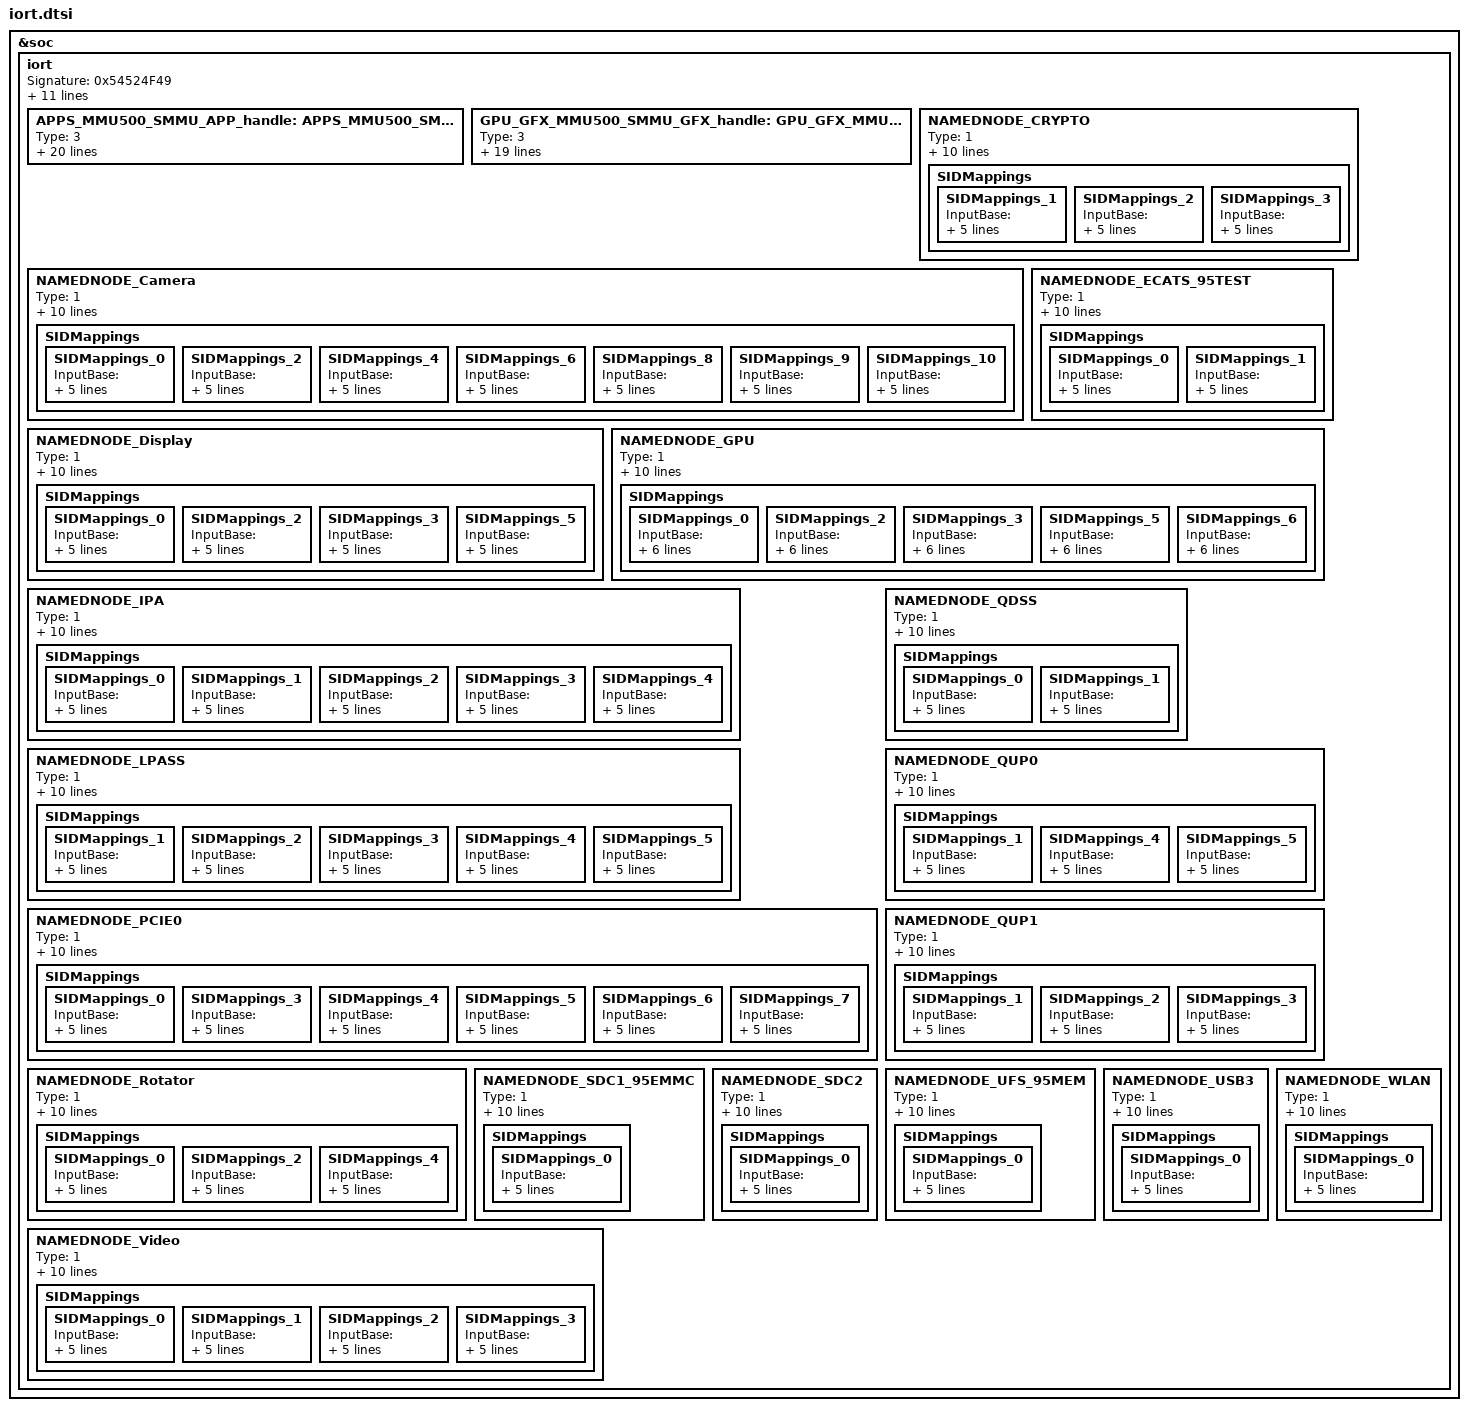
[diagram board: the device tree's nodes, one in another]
/** SMMU IORT Device Tree for clarence_1.0.

This file is automatically generated.
SMMU Base Address and Span information based on Chip Version: clarence_v1.0_p3q3r41_MTO.
Interrupt information based on Interrupt Map Version: Clarence_v1.0_p3q3r41_MTO_tmess_update.
SMMU SID Mappings based on http://ipcatalog.qualcomm.com/hsr/1914 - clarence.sid.mapping.xlsx Version 28.0.

Copyright (c) 2022 Qualcomm Technologies, Inc.
All Rights Reserved.
Confidential and Proprietary - Qualcomm Technologies, Inc.
*/

#include <iort_defines.h>
&soc{
  iort {
    Signature = <0x54524F49>;
    Revision = <1>;
    Checksum = <0>;
    OEMID = ACPI_OEM_ID;
    OEMTableID = <ACPI_OEM_TABLE_ID>;
    OEMRevision = <ACPI_OEM_REVISION>;
    CreatorID = <ACPI_CREATOR_ID>;
    CreatorRevision = <ACPI_CREATOR_REVISION>;
    NumberofIORTNodes = <20>;
    Reserved = <0>;
    instance_handles = < &APPS_MMU500_SMMU_APP_handle  &GPU_GFX_MMU500_SMMU_GFX_handle >;
    
    APPS_MMU500_SMMU_APP_handle:APPS_MMU500_SMMU_APP {
      Type = <3>;
      Revision = <1>;
      Reserved = <0>;
      NumberofMappings = <0>;
      BaseAddress = <0x15000000>; 
      Span = <0x00080000>; 
      Flags = <3>;
      Model = <3>;
      NumContextInterrupts = <96>;
      NumPMUInterrupts = <7>;
      NSGIRPT_GSIV = <97>;
      NSGIRPT_FLAGS = <0>;
      NSGCFGIRPT_GSIV = <0>;
      NSGCFGIRPT_FLAGS = <0>;
      ContextInterrupts = <126 127 128 702 703 129 130 131 132 133 134 135 136 137 138 139 140 141 142 143 144 145 146 147 148 149 150 213 214 215 216 217 218 219 220 221 222 223 224 347 348 349 350 351 352 353 354 355 356 357 358 359 360 361 362 363 364 365 366 367 368 369 370 371 372 373 374 375 376 377 427 428 429 430 431 432 433 434 435 436 437 438 439 440 441 450 451 444 453 738 455 456 457 721 722 723 >;
      ContextInterruptFlags = <0 0 0 0 0 0 0 0 0 0 0 0 0 0 0 0 0 0 0 0 0 0 0 0 0 0 0 0 0 0 0 0 0 0 0 0 0 0 0 0 0 0 0 0 0 0 0 0 0 0 0 0 0 0 0 0 0 0 0 0 0 0 0 0 0 0 0 0 0 0 0 0 0 0 0 0 0 0 0 0 0 0 0 0 0 0 0 0 0 0 0 0 0 0 0 0 >;
      PMUInterrupts = <100 101 102 103 104 105 458 >;
      PMUInterruptFlags = <0 0 0 0 0 0 0 >;
      SIDMAPPING =<0>;
      };
    GPU_GFX_MMU500_SMMU_GFX_handle:GPU_GFX_MMU500_SMMU_GFX {
      Type = <3>;
      Revision = <1>;
      Reserved = <0>;
      NumberofMappings = <0>;
      BaseAddress = <0x03da0000>; 
      Span = <0x00008000>; 
      Flags = <3>;
      Model = <3>;
      NumContextInterrupts = <8>;
      NumPMUInterrupts = <2>;
      NSGIRPT_GSIV = <705>;
      NSGIRPT_FLAGS = <0>;
      NSGCFGIRPT_GSIV = <0>;
      NSGCFGIRPT_FLAGS = <0>;
      ContextInterrupts = <710 711 712 713 714 715 716 717 >;
      ContextInterruptFlags = <0 0 0 0 0 0 0 0 >;
      PMUInterrupts = <708 709 >;
      PMUInterruptFlags = <0 0 >;
      SIDMAPPING =<0>;
      };
    
    
    NAMEDNODE_CRYPTO {
      Type = <1>;
      Revision = <1>;
      Reserved = <0>;
      NumberofMappings = <3>;
      NodeFlags = <0>;
      CacheCoherency = <0>;
      AllocationHints = <0>;
      Reserved1 = <0>;
      MemAccessFlags = <0>;
      DeviceMemAddressSize = <36>;
      DevObjectName = "CRYPTO";
      SIDMappings {
        SIDMappings_1 {
          InputBase = <(
              (IORT_WORLD_ID_NON_SECURE << IORT_WORLD_ID_SHIFT) |
              (IORT_DYNAMIC_MAPPING_NO << IORT_DYNAMIC_MAPPING_SHIFT) |
              (IORT_TRANSLATION_TYPE_NESTED << IORT_TRANSLATION_TYPE_SHIFT) |
              (1))>;
          NumIDs = <1>;
          OutputBase = <0x00000481>;
          Flags = <0>;
          OutputReference = <&APPS_MMU500_SMMU_APP_handle>;
        };
        SIDMappings_2 {
          InputBase = <(
              (IORT_WORLD_ID_NON_SECURE << IORT_WORLD_ID_SHIFT) |
              (IORT_DYNAMIC_MAPPING_NO << IORT_DYNAMIC_MAPPING_SHIFT) |
              (IORT_TRANSLATION_TYPE_NESTED << IORT_TRANSLATION_TYPE_SHIFT) |
              (2))>;
          NumIDs = <1>;
          OutputBase = <0x00000480>;
          Flags = <0>;
          OutputReference = <&APPS_MMU500_SMMU_APP_handle>;
        };
        SIDMappings_3 {
          InputBase = <(
              (IORT_WORLD_ID_NON_SECURE << IORT_WORLD_ID_SHIFT) |
              (IORT_DYNAMIC_MAPPING_NO << IORT_DYNAMIC_MAPPING_SHIFT) |
              (IORT_TRANSLATION_TYPE_NESTED << IORT_TRANSLATION_TYPE_SHIFT) |
              (3))>;
          NumIDs = <1>;
          OutputBase = <0x00000483>;
          Flags = <0>;
          OutputReference = <&APPS_MMU500_SMMU_APP_handle>;
        };
      };
    };
    NAMEDNODE_Camera {
      Type = <1>;
      Revision = <1>;
      Reserved = <0>;
      NumberofMappings = <7>;
      NodeFlags = <0>;
      CacheCoherency = <0>;
      AllocationHints = <0>;
      Reserved1 = <0>;
      MemAccessFlags = <0>;
      DeviceMemAddressSize = <36>;
      DevObjectName = "CAMERA";
      SIDMappings {
        SIDMappings_0 {
          InputBase = <(
              (IORT_WORLD_ID_NON_SECURE << IORT_WORLD_ID_SHIFT) |
              (IORT_DYNAMIC_MAPPING_NO << IORT_DYNAMIC_MAPPING_SHIFT) |
              (IORT_TRANSLATION_TYPE_NESTED << IORT_TRANSLATION_TYPE_SHIFT) |
              (0))>;
          NumIDs = <1>;
          OutputBase = <0x04200880>;
          Flags = <0>;
          OutputReference = <&APPS_MMU500_SMMU_APP_handle>;
        };
        SIDMappings_2 {
          InputBase = <(
              (IORT_WORLD_ID_NON_SECURE << IORT_WORLD_ID_SHIFT) |
              (IORT_DYNAMIC_MAPPING_NO << IORT_DYNAMIC_MAPPING_SHIFT) |
              (IORT_TRANSLATION_TYPE_NESTED << IORT_TRANSLATION_TYPE_SHIFT) |
              (2))>;
          NumIDs = <1>;
          OutputBase = <0x00001800>;
          Flags = <0>;
          OutputReference = <&APPS_MMU500_SMMU_APP_handle>;
        };
        SIDMappings_4 {
          InputBase = <(
              (IORT_WORLD_ID_NON_SECURE << IORT_WORLD_ID_SHIFT) |
              (IORT_DYNAMIC_MAPPING_NO << IORT_DYNAMIC_MAPPING_SHIFT) |
              (IORT_TRANSLATION_TYPE_NESTED << IORT_TRANSLATION_TYPE_SHIFT) |
              (4))>;
          NumIDs = <1>;
          OutputBase = <0x00001820>;
          Flags = <0>;
          OutputReference = <&APPS_MMU500_SMMU_APP_handle>;
        };
        SIDMappings_6 {
          InputBase = <(
              (IORT_WORLD_ID_NON_SECURE << IORT_WORLD_ID_SHIFT) |
              (IORT_DYNAMIC_MAPPING_NO << IORT_DYNAMIC_MAPPING_SHIFT) |
              (IORT_TRANSLATION_TYPE_NESTED << IORT_TRANSLATION_TYPE_SHIFT) |
              (6))>;
          NumIDs = <1>;
          OutputBase = <0x00a01840>;
          Flags = <0>;
          OutputReference = <&APPS_MMU500_SMMU_APP_handle>;
        };
        SIDMappings_8 {
          InputBase = <(
              (IORT_WORLD_ID_NON_SECURE << IORT_WORLD_ID_SHIFT) |
              (IORT_DYNAMIC_MAPPING_NO << IORT_DYNAMIC_MAPPING_SHIFT) |
              (IORT_TRANSLATION_TYPE_NESTED << IORT_TRANSLATION_TYPE_SHIFT) |
              (8))>;
          NumIDs = <1>;
          OutputBase = <0x00001900>;
          Flags = <0>;
          OutputReference = <&APPS_MMU500_SMMU_APP_handle>;
        };
        SIDMappings_9 {
          InputBase = <(
              (IORT_WORLD_ID_NON_SECURE << IORT_WORLD_ID_SHIFT) |
              (IORT_DYNAMIC_MAPPING_NO << IORT_DYNAMIC_MAPPING_SHIFT) |
              (IORT_TRANSLATION_TYPE_NESTED << IORT_TRANSLATION_TYPE_SHIFT) |
              (9))>;
          NumIDs = <1>;
          OutputBase = <0x00001920>;
          Flags = <0>;
          OutputReference = <&APPS_MMU500_SMMU_APP_handle>;
        };
        SIDMappings_10 {
          InputBase = <(
              (IORT_WORLD_ID_NON_SECURE << IORT_WORLD_ID_SHIFT) |
              (IORT_DYNAMIC_MAPPING_NO << IORT_DYNAMIC_MAPPING_SHIFT) |
              (IORT_TRANSLATION_TYPE_NESTED << IORT_TRANSLATION_TYPE_SHIFT) |
              (10))>;
          NumIDs = <1>;
          OutputBase = <0x00001940>;
          Flags = <0>;
          OutputReference = <&APPS_MMU500_SMMU_APP_handle>;
        };
      };
    };
    NAMEDNODE_Display {
      Type = <1>;
      Revision = <1>;
      Reserved = <0>;
      NumberofMappings = <4>;
      NodeFlags = <0>;
      CacheCoherency = <0>;
      AllocationHints = <0>;
      Reserved1 = <0>;
      MemAccessFlags = <0>;
      DeviceMemAddressSize = <36>;
      DevObjectName = "DISPLAY";
      SIDMappings {
        SIDMappings_0 {
          InputBase = <(
              (IORT_WORLD_ID_NON_SECURE << IORT_WORLD_ID_SHIFT) |
              (IORT_DYNAMIC_MAPPING_NO << IORT_DYNAMIC_MAPPING_SHIFT) |
              (IORT_TRANSLATION_TYPE_NESTED << IORT_TRANSLATION_TYPE_SHIFT) |
              (0))>;
          NumIDs = <1>;
          OutputBase = <0x04020800>;
          Flags = <0>;
          OutputReference = <&APPS_MMU500_SMMU_APP_handle>;
        };
        SIDMappings_2 {
          InputBase = <(
              (IORT_WORLD_ID_NON_SECURE << IORT_WORLD_ID_SHIFT) |
              (IORT_DYNAMIC_MAPPING_YES_DEFAULT << IORT_DYNAMIC_MAPPING_SHIFT) |
              (IORT_TRANSLATION_TYPE_NESTED << IORT_TRANSLATION_TYPE_SHIFT) |
              (2))>;
          NumIDs = <1>;
          OutputBase = <0x00000801>;
          Flags = <0>;
          OutputReference = <&APPS_MMU500_SMMU_APP_handle>;
        };
        SIDMappings_3 {
          InputBase = <(
              (IORT_WORLD_ID_NON_SECURE << IORT_WORLD_ID_SHIFT) |
              (IORT_DYNAMIC_MAPPING_NO << IORT_DYNAMIC_MAPPING_SHIFT) |
              (IORT_TRANSLATION_TYPE_NESTED << IORT_TRANSLATION_TYPE_SHIFT) |
              (3))>;
          NumIDs = <1>;
          OutputBase = <0x04020804>;
          Flags = <0>;
          OutputReference = <&APPS_MMU500_SMMU_APP_handle>;
        };
        SIDMappings_5 {
          InputBase = <(
              (IORT_WORLD_ID_NON_SECURE << IORT_WORLD_ID_SHIFT) |
              (IORT_DYNAMIC_MAPPING_YES_DEFAULT << IORT_DYNAMIC_MAPPING_SHIFT) |
              (IORT_TRANSLATION_TYPE_NESTED << IORT_TRANSLATION_TYPE_SHIFT) |
              (5))>;
          NumIDs = <1>;
          OutputBase = <0x00000c01>;
          Flags = <0>;
          OutputReference = <&APPS_MMU500_SMMU_APP_handle>;
        };
      };
    };
    NAMEDNODE_ECATS_95TEST {
      Type = <1>;
      Revision = <1>;
      Reserved = <0>;
      NumberofMappings = <2>;
      NodeFlags = <0>;
      CacheCoherency = <0>;
      AllocationHints = <0>;
      Reserved1 = <0>;
      MemAccessFlags = <0>;
      DeviceMemAddressSize = <36>;
      DevObjectName = "ECATS_TEST";
      SIDMappings {
        SIDMappings_0 {
          InputBase = <(
              (IORT_WORLD_ID_NON_SECURE << IORT_WORLD_ID_SHIFT) |
              (IORT_DYNAMIC_MAPPING_NO << IORT_DYNAMIC_MAPPING_SHIFT) |
              (IORT_TRANSLATION_TYPE_NESTED << IORT_TRANSLATION_TYPE_SHIFT) |
              (0))>;
          NumIDs = <1>;
          OutputBase = <0x000007e0>;
          Flags = <0>;
          OutputReference = <&APPS_MMU500_SMMU_APP_handle>;
        };
        SIDMappings_1 {
          InputBase = <(
              (IORT_WORLD_ID_NON_SECURE << IORT_WORLD_ID_SHIFT) |
              (IORT_DYNAMIC_MAPPING_NO << IORT_DYNAMIC_MAPPING_SHIFT) |
              (IORT_TRANSLATION_TYPE_NESTED << IORT_TRANSLATION_TYPE_SHIFT) |
              (1))>;
          NumIDs = <1>;
          OutputBase = <0x000007e1>;
          Flags = <0>;
          OutputReference = <&APPS_MMU500_SMMU_APP_handle>;
        };
      };
    };
    NAMEDNODE_GPU {
      Type = <1>;
      Revision = <1>;
      Reserved = <0>;
      NumberofMappings = <5>;
      NodeFlags = <0>;
      CacheCoherency = <0>;
      AllocationHints = <0>;
      Reserved1 = <0>;
      MemAccessFlags = <0>;
      DeviceMemAddressSize = <36>;
      DevObjectName = "GPU";
      SIDMappings {
        SIDMappings_0 {
          InputBase = <(
              (IORT_WORLD_ID_NON_SECURE << IORT_WORLD_ID_SHIFT) |
              (IORT_DYNAMIC_MAPPING_NO << IORT_DYNAMIC_MAPPING_SHIFT) |
              (IORT_TRANSLATION_TYPE_NESTED << IORT_TRANSLATION_TYPE_SHIFT) |
              (0))>;
          NumIDs = <1>;
          OutputBase = <0x04000000>;
          Flags = <0>;
          OutputReference = <&GPU_GFX_MMU500_SMMU_GFX_handle>;
        };
        SIDMappings_2 {
          InputBase = <(
              (IORT_WORLD_ID_NON_SECURE << IORT_WORLD_ID_SHIFT) |
              (IORT_DYNAMIC_MAPPING_NO << IORT_DYNAMIC_MAPPING_SHIFT) |
              (IORT_TRANSLATION_TYPE_NESTED << IORT_TRANSLATION_TYPE_SHIFT) |
              (2))>;
          NumIDs = <1>;
          OutputBase = <0x04000001>;
          Flags = <0>;
          OutputReference = <&GPU_GFX_MMU500_SMMU_GFX_handle>;
        };
        SIDMappings_3 {
          InputBase = <(
              (IORT_WORLD_ID_NON_SECURE << IORT_WORLD_ID_SHIFT) |
              (IORT_DYNAMIC_MAPPING_NO << IORT_DYNAMIC_MAPPING_SHIFT) |
              (IORT_TRANSLATION_TYPE_NESTED << IORT_TRANSLATION_TYPE_SHIFT) |
              (3))>;
          NumIDs = <1>;
          OutputBase = <0x04000002>;
          Flags = <0>;
          OutputReference = <&GPU_GFX_MMU500_SMMU_GFX_handle>;
        };
        SIDMappings_5 {
          InputBase = <(
              (IORT_WORLD_ID_NON_SECURE << IORT_WORLD_ID_SHIFT) |
              (IORT_DYNAMIC_MAPPING_NO << IORT_DYNAMIC_MAPPING_SHIFT) |
              (IORT_TRANSLATION_TYPE_NESTED << IORT_TRANSLATION_TYPE_SHIFT) |
              (5))>;
          NumIDs = <1>;
          OutputBase = <0x04000007>;
          Flags = <0>;
          OutputReference = <&GPU_GFX_MMU500_SMMU_GFX_handle>;
        };
        SIDMappings_6 {
          InputBase = <(
              (IORT_WORLD_ID_NON_SECURE << IORT_WORLD_ID_SHIFT) |
              (IORT_DYNAMIC_MAPPING_NO << IORT_DYNAMIC_MAPPING_SHIFT) |
              (IORT_TRANSLATION_TYPE_NESTED << IORT_TRANSLATION_TYPE_SHIFT) |
              (6))>;
          NumIDs = <1>;
          OutputBase = <0x04000009>;
          Flags = <0>;
          OutputReference = <&GPU_GFX_MMU500_SMMU_GFX_handle>;
        };
      };
    };
    NAMEDNODE_IPA {
      Type = <1>;
      Revision = <1>;
      Reserved = <0>;
      NumberofMappings = <5>;
      NodeFlags = <0>;
      CacheCoherency = <0>;
      AllocationHints = <0>;
      Reserved1 = <0>;
      MemAccessFlags = <0>;
      DeviceMemAddressSize = <36>;
      DevObjectName = "IPA";
      SIDMappings {
        SIDMappings_0 {
          InputBase = <(
              (IORT_WORLD_ID_NON_SECURE << IORT_WORLD_ID_SHIFT) |
              (IORT_DYNAMIC_MAPPING_NO << IORT_DYNAMIC_MAPPING_SHIFT) |
              (IORT_TRANSLATION_TYPE_NESTED << IORT_TRANSLATION_TYPE_SHIFT) |
              (0))>;
          NumIDs = <1>;
          OutputBase = <0x000004a0>;
          Flags = <0>;
          OutputReference = <&APPS_MMU500_SMMU_APP_handle>;
        };
        SIDMappings_1 {
          InputBase = <(
              (IORT_WORLD_ID_NON_SECURE << IORT_WORLD_ID_SHIFT) |
              (IORT_DYNAMIC_MAPPING_NO << IORT_DYNAMIC_MAPPING_SHIFT) |
              (IORT_TRANSLATION_TYPE_NESTED << IORT_TRANSLATION_TYPE_SHIFT) |
              (1))>;
          NumIDs = <1>;
          OutputBase = <0x000004a1>;
          Flags = <0>;
          OutputReference = <&APPS_MMU500_SMMU_APP_handle>;
        };
        SIDMappings_2 {
          InputBase = <(
              (IORT_WORLD_ID_NON_SECURE << IORT_WORLD_ID_SHIFT) |
              (IORT_DYNAMIC_MAPPING_NO << IORT_DYNAMIC_MAPPING_SHIFT) |
              (IORT_TRANSLATION_TYPE_NESTED << IORT_TRANSLATION_TYPE_SHIFT) |
              (2))>;
          NumIDs = <1>;
          OutputBase = <0x000004a2>;
          Flags = <0>;
          OutputReference = <&APPS_MMU500_SMMU_APP_handle>;
        };
        SIDMappings_3 {
          InputBase = <(
              (IORT_WORLD_ID_NON_SECURE << IORT_WORLD_ID_SHIFT) |
              (IORT_DYNAMIC_MAPPING_NO << IORT_DYNAMIC_MAPPING_SHIFT) |
              (IORT_TRANSLATION_TYPE_NESTED << IORT_TRANSLATION_TYPE_SHIFT) |
              (3))>;
          NumIDs = <1>;
          OutputBase = <0x000004a3>;
          Flags = <0>;
          OutputReference = <&APPS_MMU500_SMMU_APP_handle>;
        };
        SIDMappings_4 {
          InputBase = <(
              (IORT_WORLD_ID_NON_SECURE << IORT_WORLD_ID_SHIFT) |
              (IORT_DYNAMIC_MAPPING_NO << IORT_DYNAMIC_MAPPING_SHIFT) |
              (IORT_TRANSLATION_TYPE_NESTED << IORT_TRANSLATION_TYPE_SHIFT) |
              (4))>;
          NumIDs = <1>;
          OutputBase = <0x000004a4>;
          Flags = <0>;
          OutputReference = <&APPS_MMU500_SMMU_APP_handle>;
        };
      };
    };
    NAMEDNODE_LPASS {
      Type = <1>;
      Revision = <1>;
      Reserved = <0>;
      NumberofMappings = <5>;
      NodeFlags = <0>;
      CacheCoherency = <0>;
      AllocationHints = <0>;
      Reserved1 = <0>;
      MemAccessFlags = <0>;
      DeviceMemAddressSize = <36>;
      DevObjectName = "LPASS";
      SIDMappings {
        SIDMappings_1 {
          InputBase = <(
              (IORT_WORLD_ID_NON_SECURE << IORT_WORLD_ID_SHIFT) |
              (IORT_DYNAMIC_MAPPING_NO << IORT_DYNAMIC_MAPPING_SHIFT) |
              (IORT_TRANSLATION_TYPE_NESTED << IORT_TRANSLATION_TYPE_SHIFT) |
              (1))>;
          NumIDs = <1>;
          OutputBase = <0x00001001>;
          Flags = <0>;
          OutputReference = <&APPS_MMU500_SMMU_APP_handle>;
        };
        SIDMappings_2 {
          InputBase = <(
              (IORT_WORLD_ID_NON_SECURE << IORT_WORLD_ID_SHIFT) |
              (IORT_DYNAMIC_MAPPING_NO << IORT_DYNAMIC_MAPPING_SHIFT) |
              (IORT_TRANSLATION_TYPE_NESTED << IORT_TRANSLATION_TYPE_SHIFT) |
              (2))>;
          NumIDs = <1>;
          OutputBase = <0x00001003>;
          Flags = <0>;
          OutputReference = <&APPS_MMU500_SMMU_APP_handle>;
        };
        SIDMappings_3 {
          InputBase = <(
              (IORT_WORLD_ID_NON_SECURE << IORT_WORLD_ID_SHIFT) |
              (IORT_DYNAMIC_MAPPING_NO << IORT_DYNAMIC_MAPPING_SHIFT) |
              (IORT_TRANSLATION_TYPE_NESTED << IORT_TRANSLATION_TYPE_SHIFT) |
              (3))>;
          NumIDs = <1>;
          OutputBase = <0x00001004>;
          Flags = <0>;
          OutputReference = <&APPS_MMU500_SMMU_APP_handle>;
        };
        SIDMappings_4 {
          InputBase = <(
              (IORT_WORLD_ID_NON_SECURE << IORT_WORLD_ID_SHIFT) |
              (IORT_DYNAMIC_MAPPING_NO << IORT_DYNAMIC_MAPPING_SHIFT) |
              (IORT_TRANSLATION_TYPE_NESTED << IORT_TRANSLATION_TYPE_SHIFT) |
              (4))>;
          NumIDs = <1>;
          OutputBase = <0x00001005>;
          Flags = <0>;
          OutputReference = <&APPS_MMU500_SMMU_APP_handle>;
        };
        SIDMappings_5 {
          InputBase = <(
              (IORT_WORLD_ID_NON_SECURE << IORT_WORLD_ID_SHIFT) |
              (IORT_DYNAMIC_MAPPING_NO << IORT_DYNAMIC_MAPPING_SHIFT) |
              (IORT_TRANSLATION_TYPE_NESTED << IORT_TRANSLATION_TYPE_SHIFT) |
              (5))>;
          NumIDs = <1>;
          OutputBase = <0x0000100f>;
          Flags = <0>;
          OutputReference = <&APPS_MMU500_SMMU_APP_handle>;
        };
      };
    };
    NAMEDNODE_PCIE0 {
      Type = <1>;
      Revision = <1>;
      Reserved = <0>;
      NumberofMappings = <6>;
      NodeFlags = <0>;
      CacheCoherency = <0>;
      AllocationHints = <0>;
      Reserved1 = <0>;
      MemAccessFlags = <0>;
      DeviceMemAddressSize = <36>;
      DevObjectName = "PCIE0";
      SIDMappings {
        SIDMappings_0 {
          InputBase = <(
              (IORT_WORLD_ID_NON_SECURE << IORT_WORLD_ID_SHIFT) |
              (IORT_DYNAMIC_MAPPING_NO << IORT_DYNAMIC_MAPPING_SHIFT) |
              (IORT_TRANSLATION_TYPE_NESTED << IORT_TRANSLATION_TYPE_SHIFT) |
              (0))>;
          NumIDs = <1>;
          OutputBase = <0x00011400>;
          Flags = <0>;
          OutputReference = <&APPS_MMU500_SMMU_APP_handle>;
        };
        SIDMappings_3 {
          InputBase = <(
              (IORT_WORLD_ID_NON_SECURE << IORT_WORLD_ID_SHIFT) |
              (IORT_DYNAMIC_MAPPING_NO << IORT_DYNAMIC_MAPPING_SHIFT) |
              (IORT_TRANSLATION_TYPE_NESTED << IORT_TRANSLATION_TYPE_SHIFT) |
              (3))>;
          NumIDs = <1>;
          OutputBase = <0x00031404>;
          Flags = <0>;
          OutputReference = <&APPS_MMU500_SMMU_APP_handle>;
        };
        SIDMappings_4 {
          InputBase = <(
              (IORT_WORLD_ID_NON_SECURE << IORT_WORLD_ID_SHIFT) |
              (IORT_DYNAMIC_MAPPING_NO << IORT_DYNAMIC_MAPPING_SHIFT) |
              (IORT_TRANSLATION_TYPE_NESTED << IORT_TRANSLATION_TYPE_SHIFT) |
              (4))>;
          NumIDs = <1>;
          OutputBase = <0x00071408>;
          Flags = <0>;
          OutputReference = <&APPS_MMU500_SMMU_APP_handle>;
        };
        SIDMappings_5 {
          InputBase = <(
              (IORT_WORLD_ID_NON_SECURE << IORT_WORLD_ID_SHIFT) |
              (IORT_DYNAMIC_MAPPING_NO << IORT_DYNAMIC_MAPPING_SHIFT) |
              (IORT_TRANSLATION_TYPE_NESTED << IORT_TRANSLATION_TYPE_SHIFT) |
              (5))>;
          NumIDs = <1>;
          OutputBase = <0x000f1410>;
          Flags = <0>;
          OutputReference = <&APPS_MMU500_SMMU_APP_handle>;
        };
        SIDMappings_6 {
          InputBase = <(
              (IORT_WORLD_ID_NON_SECURE << IORT_WORLD_ID_SHIFT) |
              (IORT_DYNAMIC_MAPPING_NO << IORT_DYNAMIC_MAPPING_SHIFT) |
              (IORT_TRANSLATION_TYPE_NESTED << IORT_TRANSLATION_TYPE_SHIFT) |
              (6))>;
          NumIDs = <1>;
          OutputBase = <0x001f1420>;
          Flags = <0>;
          OutputReference = <&APPS_MMU500_SMMU_APP_handle>;
        };
        SIDMappings_7 {
          InputBase = <(
              (IORT_WORLD_ID_NON_SECURE << IORT_WORLD_ID_SHIFT) |
              (IORT_DYNAMIC_MAPPING_NO << IORT_DYNAMIC_MAPPING_SHIFT) |
              (IORT_TRANSLATION_TYPE_NESTED << IORT_TRANSLATION_TYPE_SHIFT) |
              (7))>;
          NumIDs = <1>;
          OutputBase = <0x003f1440>;
          Flags = <0>;
          OutputReference = <&APPS_MMU500_SMMU_APP_handle>;
        };
      };
    };
    NAMEDNODE_QDSS {
      Type = <1>;
      Revision = <1>;
      Reserved = <0>;
      NumberofMappings = <2>;
      NodeFlags = <0>;
      CacheCoherency = <0>;
      AllocationHints = <0>;
      Reserved1 = <0>;
      MemAccessFlags = <0>;
      DeviceMemAddressSize = <36>;
      DevObjectName = "QDSS";
      SIDMappings {
        SIDMappings_0 {
          InputBase = <(
              (IORT_WORLD_ID_NON_SECURE << IORT_WORLD_ID_SHIFT) |
              (IORT_DYNAMIC_MAPPING_NO << IORT_DYNAMIC_MAPPING_SHIFT) |
              (IORT_TRANSLATION_TYPE_NESTED << IORT_TRANSLATION_TYPE_SHIFT) |
              (0))>;
          NumIDs = <1>;
          OutputBase = <0x00200500>;
          Flags = <0>;
          OutputReference = <&APPS_MMU500_SMMU_APP_handle>;
        };
        SIDMappings_1 {
          InputBase = <(
              (IORT_WORLD_ID_NON_SECURE << IORT_WORLD_ID_SHIFT) |
              (IORT_DYNAMIC_MAPPING_NO << IORT_DYNAMIC_MAPPING_SHIFT) |
              (IORT_TRANSLATION_TYPE_NESTED << IORT_TRANSLATION_TYPE_SHIFT) |
              (1))>;
          NumIDs = <1>;
          OutputBase = <0x000004e0>;
          Flags = <0>;
          OutputReference = <&APPS_MMU500_SMMU_APP_handle>;
        };
      };
    };
    NAMEDNODE_QUP0 {
      Type = <1>;
      Revision = <1>;
      Reserved = <0>;
      NumberofMappings = <3>;
      NodeFlags = <0>;
      CacheCoherency = <0>;
      AllocationHints = <0>;
      Reserved1 = <0>;
      MemAccessFlags = <0>;
      DeviceMemAddressSize = <36>;
      DevObjectName = "QUP0";
      SIDMappings {
        SIDMappings_1 {
          InputBase = <(
              (IORT_WORLD_ID_NON_SECURE << IORT_WORLD_ID_SHIFT) |
              (IORT_DYNAMIC_MAPPING_NO << IORT_DYNAMIC_MAPPING_SHIFT) |
              (IORT_TRANSLATION_TYPE_NESTED << IORT_TRANSLATION_TYPE_SHIFT) |
              (1))>;
          NumIDs = <1>;
          OutputBase = <0x00000163>;
          Flags = <0>;
          OutputReference = <&APPS_MMU500_SMMU_APP_handle>;
        };
        SIDMappings_4 {
          InputBase = <(
              (IORT_WORLD_ID_NON_SECURE << IORT_WORLD_ID_SHIFT) |
              (IORT_DYNAMIC_MAPPING_NO << IORT_DYNAMIC_MAPPING_SHIFT) |
              (IORT_TRANSLATION_TYPE_NESTED << IORT_TRANSLATION_TYPE_SHIFT) |
              (4))>;
          NumIDs = <1>;
          OutputBase = <0x00000176>;
          Flags = <0>;
          OutputReference = <&APPS_MMU500_SMMU_APP_handle>;
        };
        SIDMappings_5 {
          InputBase = <(
              (IORT_WORLD_ID_NON_SECURE << IORT_WORLD_ID_SHIFT) |
              (IORT_DYNAMIC_MAPPING_NO << IORT_DYNAMIC_MAPPING_SHIFT) |
              (IORT_TRANSLATION_TYPE_NESTED << IORT_TRANSLATION_TYPE_SHIFT) |
              (5))>;
          NumIDs = <1>;
          OutputBase = <0x00000178>;
          Flags = <0>;
          OutputReference = <&APPS_MMU500_SMMU_APP_handle>;
        };
      };
    };
    NAMEDNODE_QUP1 {
      Type = <1>;
      Revision = <1>;
      Reserved = <0>;
      NumberofMappings = <3>;
      NodeFlags = <0>;
      CacheCoherency = <0>;
      AllocationHints = <0>;
      Reserved1 = <0>;
      MemAccessFlags = <0>;
      DeviceMemAddressSize = <36>;
      DevObjectName = "QUP1";
      SIDMappings {
        SIDMappings_1 {
          InputBase = <(
              (IORT_WORLD_ID_NON_SECURE << IORT_WORLD_ID_SHIFT) |
              (IORT_DYNAMIC_MAPPING_NO << IORT_DYNAMIC_MAPPING_SHIFT) |
              (IORT_TRANSLATION_TYPE_NESTED << IORT_TRANSLATION_TYPE_SHIFT) |
              (1))>;
          NumIDs = <1>;
          OutputBase = <0x00000416>;
          Flags = <0>;
          OutputReference = <&APPS_MMU500_SMMU_APP_handle>;
        };
        SIDMappings_2 {
          InputBase = <(
              (IORT_WORLD_ID_NON_SECURE << IORT_WORLD_ID_SHIFT) |
              (IORT_DYNAMIC_MAPPING_NO << IORT_DYNAMIC_MAPPING_SHIFT) |
              (IORT_TRANSLATION_TYPE_NESTED << IORT_TRANSLATION_TYPE_SHIFT) |
              (2))>;
          NumIDs = <1>;
          OutputBase = <0x00000418>;
          Flags = <0>;
          OutputReference = <&APPS_MMU500_SMMU_APP_handle>;
        };
        SIDMappings_3 {
          InputBase = <(
              (IORT_WORLD_ID_NON_SECURE << IORT_WORLD_ID_SHIFT) |
              (IORT_DYNAMIC_MAPPING_NO << IORT_DYNAMIC_MAPPING_SHIFT) |
              (IORT_TRANSLATION_TYPE_NESTED << IORT_TRANSLATION_TYPE_SHIFT) |
              (3))>;
          NumIDs = <1>;
          OutputBase = <0x00000403>;
          Flags = <0>;
          OutputReference = <&APPS_MMU500_SMMU_APP_handle>;
        };
      };
    };
    NAMEDNODE_Rotator {
      Type = <1>;
      Revision = <1>;
      Reserved = <0>;
      NumberofMappings = <3>;
      NodeFlags = <0>;
      CacheCoherency = <0>;
      AllocationHints = <0>;
      Reserved1 = <0>;
      MemAccessFlags = <0>;
      DeviceMemAddressSize = <36>;
      DevObjectName = "ROTATOR";
      SIDMappings {
        SIDMappings_0 {
          InputBase = <(
              (IORT_WORLD_ID_NON_SECURE << IORT_WORLD_ID_SHIFT) |
              (IORT_DYNAMIC_MAPPING_NO << IORT_DYNAMIC_MAPPING_SHIFT) |
              (IORT_TRANSLATION_TYPE_NESTED << IORT_TRANSLATION_TYPE_SHIFT) |
              (0))>;
          NumIDs = <1>;
          OutputBase = <0x0400081c>;
          Flags = <0>;
          OutputReference = <&APPS_MMU500_SMMU_APP_handle>;
        };
        SIDMappings_2 {
          InputBase = <(
              (IORT_WORLD_ID_NON_SECURE << IORT_WORLD_ID_SHIFT) |
              (IORT_DYNAMIC_MAPPING_YES_DEFAULT << IORT_DYNAMIC_MAPPING_SHIFT) |
              (IORT_TRANSLATION_TYPE_NESTED << IORT_TRANSLATION_TYPE_SHIFT) |
              (2))>;
          NumIDs = <1>;
          OutputBase = <0x0000081d>;
          Flags = <0>;
          OutputReference = <&APPS_MMU500_SMMU_APP_handle>;
        };
        SIDMappings_4 {
          InputBase = <(
              (IORT_WORLD_ID_NON_SECURE << IORT_WORLD_ID_SHIFT) |
              (IORT_DYNAMIC_MAPPING_YES_DEFAULT << IORT_DYNAMIC_MAPPING_SHIFT) |
              (IORT_TRANSLATION_TYPE_NESTED << IORT_TRANSLATION_TYPE_SHIFT) |
              (4))>;
          NumIDs = <1>;
          OutputBase = <0x00000c1d>;
          Flags = <0>;
          OutputReference = <&APPS_MMU500_SMMU_APP_handle>;
        };
      };
    };
    NAMEDNODE_SDC1_95EMMC {
      Type = <1>;
      Revision = <1>;
      Reserved = <0>;
      NumberofMappings = <1>;
      NodeFlags = <0>;
      CacheCoherency = <0>;
      AllocationHints = <0>;
      Reserved1 = <0>;
      MemAccessFlags = <0>;
      DeviceMemAddressSize = <36>;
      DevObjectName = "SDC1_EMMC";
      SIDMappings {
        SIDMappings_0 {
          InputBase = <(
              (IORT_WORLD_ID_NON_SECURE << IORT_WORLD_ID_SHIFT) |
              (IORT_DYNAMIC_MAPPING_NO << IORT_DYNAMIC_MAPPING_SHIFT) |
              (IORT_TRANSLATION_TYPE_NESTED << IORT_TRANSLATION_TYPE_SHIFT) |
              (0))>;
          NumIDs = <1>;
          OutputBase = <0x00000560>;
          Flags = <0>;
          OutputReference = <&APPS_MMU500_SMMU_APP_handle>;
        };
      };
    };
    NAMEDNODE_SDC2 {
      Type = <1>;
      Revision = <1>;
      Reserved = <0>;
      NumberofMappings = <1>;
      NodeFlags = <0>;
      CacheCoherency = <0>;
      AllocationHints = <0>;
      Reserved1 = <0>;
      MemAccessFlags = <0>;
      DeviceMemAddressSize = <36>;
      DevObjectName = "SDC2";
      SIDMappings {
        SIDMappings_0 {
          InputBase = <(
              (IORT_WORLD_ID_NON_SECURE << IORT_WORLD_ID_SHIFT) |
              (IORT_DYNAMIC_MAPPING_NO << IORT_DYNAMIC_MAPPING_SHIFT) |
              (IORT_TRANSLATION_TYPE_NESTED << IORT_TRANSLATION_TYPE_SHIFT) |
              (0))>;
          NumIDs = <1>;
          OutputBase = <0x00000140>;
          Flags = <0>;
          OutputReference = <&APPS_MMU500_SMMU_APP_handle>;
        };
      };
    };
    NAMEDNODE_UFS_95MEM {
      Type = <1>;
      Revision = <1>;
      Reserved = <0>;
      NumberofMappings = <1>;
      NodeFlags = <0>;
      CacheCoherency = <0>;
      AllocationHints = <0>;
      Reserved1 = <0>;
      MemAccessFlags = <0>;
      DeviceMemAddressSize = <36>;
      DevObjectName = "UFS_MEM";
      SIDMappings {
        SIDMappings_0 {
          InputBase = <(
              (IORT_WORLD_ID_NON_SECURE << IORT_WORLD_ID_SHIFT) |
              (IORT_DYNAMIC_MAPPING_NO << IORT_DYNAMIC_MAPPING_SHIFT) |
              (IORT_TRANSLATION_TYPE_NESTED << IORT_TRANSLATION_TYPE_SHIFT) |
              (0))>;
          NumIDs = <1>;
          OutputBase = <0x00000580>;
          Flags = <0>;
          OutputReference = <&APPS_MMU500_SMMU_APP_handle>;
        };
      };
    };
    NAMEDNODE_USB3 {
      Type = <1>;
      Revision = <1>;
      Reserved = <0>;
      NumberofMappings = <1>;
      NodeFlags = <0>;
      CacheCoherency = <0>;
      AllocationHints = <0>;
      Reserved1 = <0>;
      MemAccessFlags = <0>;
      DeviceMemAddressSize = <36>;
      DevObjectName = "USB3";
      SIDMappings {
        SIDMappings_0 {
          InputBase = <(
              (IORT_WORLD_ID_NON_SECURE << IORT_WORLD_ID_SHIFT) |
              (IORT_DYNAMIC_MAPPING_NO << IORT_DYNAMIC_MAPPING_SHIFT) |
              (IORT_TRANSLATION_TYPE_NESTED << IORT_TRANSLATION_TYPE_SHIFT) |
              (0))>;
          NumIDs = <1>;
          OutputBase = <0x00000540>;
          Flags = <0>;
          OutputReference = <&APPS_MMU500_SMMU_APP_handle>;
        };
      };
    };
    NAMEDNODE_Video {
      Type = <1>;
      Revision = <1>;
      Reserved = <0>;
      NumberofMappings = <4>;
      NodeFlags = <0>;
      CacheCoherency = <0>;
      AllocationHints = <0>;
      Reserved1 = <0>;
      MemAccessFlags = <0>;
      DeviceMemAddressSize = <36>;
      DevObjectName = "VIDEO";
      SIDMappings {
        SIDMappings_0 {
          InputBase = <(
              (IORT_WORLD_ID_NON_SECURE << IORT_WORLD_ID_SHIFT) |
              (IORT_DYNAMIC_MAPPING_NO << IORT_DYNAMIC_MAPPING_SHIFT) |
              (IORT_TRANSLATION_TYPE_NESTED << IORT_TRANSLATION_TYPE_SHIFT) |
              (0))>;
          NumIDs = <1>;
          OutputBase = <0x00201980>;
          Flags = <0>;
          OutputReference = <&APPS_MMU500_SMMU_APP_handle>;
        };
        SIDMappings_1 {
          InputBase = <(
              (IORT_WORLD_ID_NON_SECURE << IORT_WORLD_ID_SHIFT) |
              (IORT_DYNAMIC_MAPPING_NO << IORT_DYNAMIC_MAPPING_SHIFT) |
              (IORT_TRANSLATION_TYPE_NESTED << IORT_TRANSLATION_TYPE_SHIFT) |
              (1))>;
          NumIDs = <1>;
          OutputBase = <0x00041981>;
          Flags = <0>;
          OutputReference = <&APPS_MMU500_SMMU_APP_handle>;
        };
        SIDMappings_2 {
          InputBase = <(
              (IORT_WORLD_ID_NON_SECURE << IORT_WORLD_ID_SHIFT) |
              (IORT_DYNAMIC_MAPPING_NO << IORT_DYNAMIC_MAPPING_SHIFT) |
              (IORT_TRANSLATION_TYPE_NESTED << IORT_TRANSLATION_TYPE_SHIFT) |
              (2))>;
          NumIDs = <1>;
          OutputBase = <0x00001983>;
          Flags = <0>;
          OutputReference = <&APPS_MMU500_SMMU_APP_handle>;
        };
        SIDMappings_3 {
          InputBase = <(
              (IORT_WORLD_ID_NON_SECURE << IORT_WORLD_ID_SHIFT) |
              (IORT_DYNAMIC_MAPPING_NO << IORT_DYNAMIC_MAPPING_SHIFT) |
              (IORT_TRANSLATION_TYPE_NESTED << IORT_TRANSLATION_TYPE_SHIFT) |
              (3))>;
          NumIDs = <1>;
          OutputBase = <0x00201984>;
          Flags = <0>;
          OutputReference = <&APPS_MMU500_SMMU_APP_handle>;
        };
      };
    };
    NAMEDNODE_WLAN {
      Type = <1>;
      Revision = <1>;
      Reserved = <0>;
      NumberofMappings = <1>;
      NodeFlags = <0>;
      CacheCoherency = <0>;
      AllocationHints = <0>;
      Reserved1 = <0>;
      MemAccessFlags = <0>;
      DeviceMemAddressSize = <36>;
      DevObjectName = "WLAN";
      SIDMappings {
        SIDMappings_0 {
          InputBase = <(
              (IORT_WORLD_ID_NON_SECURE << IORT_WORLD_ID_SHIFT) |
              (IORT_DYNAMIC_MAPPING_NO << IORT_DYNAMIC_MAPPING_SHIFT) |
              (IORT_TRANSLATION_TYPE_NESTED << IORT_TRANSLATION_TYPE_SHIFT) |
              (0))>;
          NumIDs = <1>;
          OutputBase = <0x000104c0>;
          Flags = <0>;
          OutputReference = <&APPS_MMU500_SMMU_APP_handle>;
        };
      };
    };
  };
};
